# APM32F103x4 register map
File version: 1.0
CPU: CM3 r2p1, little endian, no MPU, no FPU, 4 interrupt priority bits
Registers are 32-bit, read-write, reset 0x0 unless marked. A register's access mark holds for its fields unless they carry their own. Offsets are from the block's base; [hi:lo] are bit positions; {n}, {i} and the like mark numbered series; 'fields as' and 'values as' point back to an identical list.

## DMA1 — DMA1 controller
Base 0x40020000
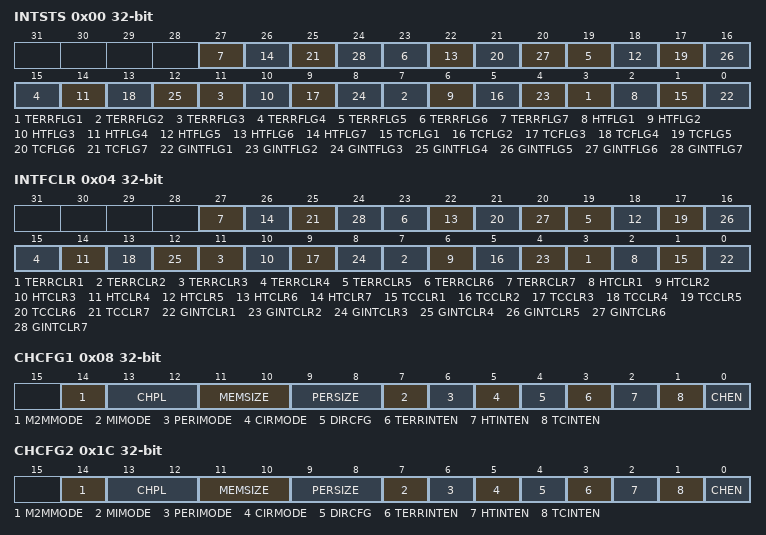
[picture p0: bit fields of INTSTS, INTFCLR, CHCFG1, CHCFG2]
0x00 INTSTS ro — DMA Interrupt status register (DMA_INTSTS)
  [4n-1] TERRFLG{n} (n=1..7) — Channel {n} Transfer Error flag
  [4n-2] HTFLG{n} (n=1..7) — Channel {n} Half Transfer Complete flag
  [4n-3] TCFLG{n} (n=1..7) — Channel {n} Transfer Complete flag
  [4n-4] GINTFLG{n} (n=1..7) — Channel {n} Global interrupt flag
0x04 INTFCLR wo — DMA Interrupt reset register (DMA_INTFCLR)
  [4n-1] TERRCLR{n} (n=1..7) — Channel {n} Transfer Error reset
  [4n-2] HTCLR{n} (n=1..7) — Channel {n} Half Transfer reset
  [4n-3] TCCLR{n} (n=1..7) — Channel {n} Transfer Complete reset
  [4n-4] GINTCLR{n} (n=1..7) — Channel {n} Global interrupt reset
0x08 CHCFG1 — DMA channel 1 configuration register
  [14] M2MMODE — Memory to memory mode
  [13:12] CHPL — Channel Priority level
  [11:10] MEMSIZE — Memory size
  [9:8] PERSIZE — Peripheral size
  [7] MIMODE — Memory increment mode
  [6] PERIMODE — Peripheral increment mode
  [5] CIRMODE — Circular mode
  [4] DIRCFG — Data transfer direction
  [3] TERRINTEN — Transfer error interrupt enable
  [2] HTINTEN — Half Transfer interrupt enable
  [1] TCINTEN — Transfer complete interrupt enable
  [0] CHEN — Channel enable
0x0C CHNDATA1 — DMA channel 1 number of data register
  [15:0] NDATA — Number of data to transfer
0x10 CHPADDR1 — DMA channel 1 peripheral address register
  [31:0] PERADDR — Peripheral address
{0x0+0x14*i} CHMADDR{i} (i=1..7) — DMA channel {i} memory address register
  [31:0] MEMADDR — Memory address
0x1C CHCFG2 — DMA channel 2 configuration register
  fields as CHCFG1
0x20 CHNDATA2 — DMA channel 2 number of data register
  [15:0] NDATA — Number of data to transfer
0x24 CHPADDR2 — DMA channel 2 peripheral address register
  [31:0] PERADDR — Peripheral address
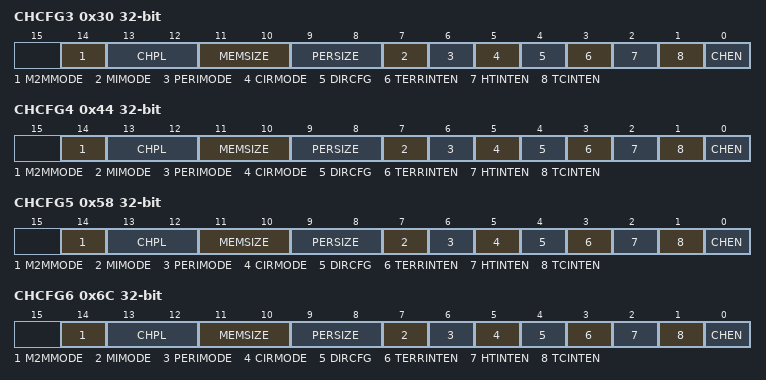
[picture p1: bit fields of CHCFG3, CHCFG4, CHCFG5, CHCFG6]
0x30 CHCFG3 — DMA channel 3 configuration register
  fields as CHCFG1
0x34 CHNDATA3 — DMA channel 3 number of data register
  [15:0] NDATA — Number of data to transfer
0x38 CHPADDR3 — DMA channel 3 peripheral address register
  [31:0] PERADDR — Peripheral address
0x44 CHCFG4 — DMA channel 4 configuration register
  fields as CHCFG1
0x48 CHNDATA4 — DMA channel 4 number of data register
  [15:0] NDATA — Number of data to transfer
0x4C CHPADDR4 — DMA channel 4 peripheral address register
  [31:0] PERADDR — Peripheral address
0x58 CHCFG5 — DMA channel 5 configuration register
  fields as CHCFG1
0x5C CHNDATA5 — DMA channel 5 number of data register
  [15:0] NDATA — Number of data to transfer
0x60 CHPADDR5 — DMA channel 5 peripheral address register
  [31:0] PERADDR — Peripheral address
0x6C CHCFG6 — DMA channel 6 configuration register
  fields as CHCFG1
0x70 CHNDATA6 — DMA channel 6 number of data register
  [15:0] NDATA — Number of data to transfer
0x74 CHPADDR6 — DMA channel 6 peripheral address register
  [31:0] PERADDR — Peripheral address
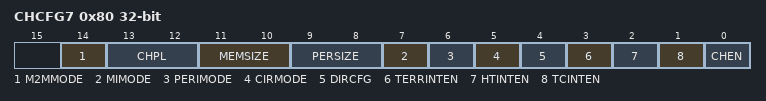
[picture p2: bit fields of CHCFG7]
0x80 CHCFG7 — DMA channel 7 configuration register
  fields as CHCFG1
0x84 CHNDATA7 — DMA channel 7 number of data register
  [15:0] NADDR — Number of data to transfer
0x88 CHPADDR7 — DMA channel 7 peripheral address register
  [31:0] PERADDR — Peripheral address

## USART1 — Universal synchronous asynchronous receiver transmitter
Base 0x40013800
Same registers: USART2 0x40004400
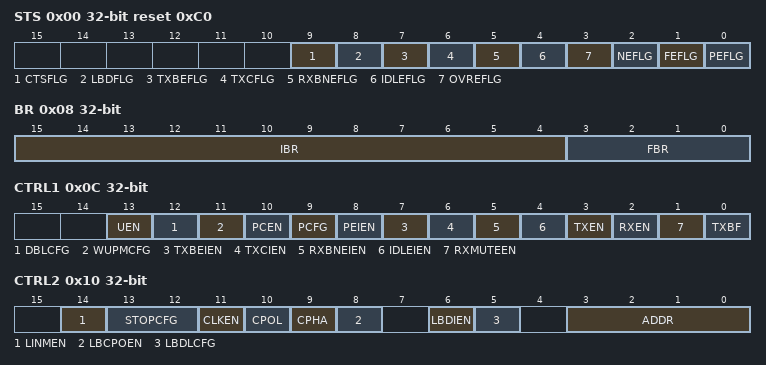
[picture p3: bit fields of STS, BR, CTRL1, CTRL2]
0x00 STS access per field reset 0xC0 — Status register
  [9] CTSFLG rw — CTS flag
  [8] LBDFLG rw — LIN break detection flag
  [7] TXBEFLG ro — Transmit data register empty
  [6] TXCFLG rw — Transmission complete
  [5] RXBNEFLG rw — Read data register not empty
  [4] IDLEFLG ro — IDLE line detected
  [3] OVREFLG ro — Overrun error
  [2] NEFLG ro — Noise error flag
  [1] FEFLG ro — Framing error
  [0] PEFLG ro — Parity error
0x04 DATA — TX Buffer Data Register
  [8:0] DATA — Data value
0x08 BR — Baud rate register
  [15:4] IBR — Integer of USARTDIV
  [3:0] FBR — Fraction of USARTDIV
0x0C CTRL1 — Control register 1
  [13] UEN — USART enable
  [12] DBLCFG — Word length
  [11] WUPMCFG — Wakeup method
  [10] PCEN — Parity control enable
  [9] PCFG — Parity selection
  [8] PEIEN — PE interrupt enable
  [7] TXBEIEN — TXBE interrupt enable
  [6] TXCIEN — Transmission complete interrupt enable
  [5] RXBNEIEN — RXBNE interrupt enable
  [4] IDLEIEN — IDLE interrupt enable
  [3] TXEN — Transmitter enable
  [2] RXEN — Receiver enable
  [1] RXMUTEEN — Receiver wakeup
  [0] TXBF — Send break
0x10 CTRL2 — Control register 2
  [14] LINMEN — LIN mode enable
  [13:12] STOPCFG — STOP bits
  [11] CLKEN — Clock enable
  [10] CPOL — Clock polarity
  [9] CPHA — Clock phase
  [8] LBCPOEN — Last bit clock pulse
  [6] LBDIEN — LIN break detection interrupt enable
  [5] LBDLCFG — lin break detection length
  [3:0] ADDR — Address of the USART node
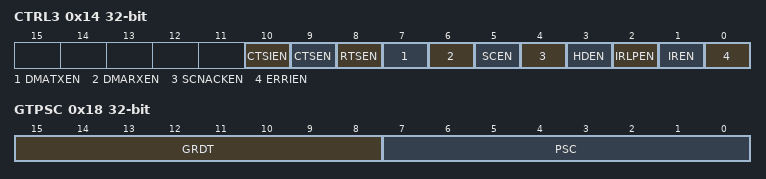
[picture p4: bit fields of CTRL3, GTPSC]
0x14 CTRL3 — Control register 3
  [10] CTSIEN — CTS interrupt enable
  [9] CTSEN — CTS enable
  [8] RTSEN — RTS enable
  [7] DMATXEN — DMA enable transmitter
  [6] DMARXEN — DMA enable receiver
  [5] SCEN — Smartcard mode enable
  [4] SCNACKEN — Smartcard NACK enable
  [3] HDEN — Half-duplex selection
  [2] IRLPEN — IrDA low-power
  [1] IREN — IrDA mode enable
  [0] ERRIEN — Error interrupt enable
0x18 GTPSC — Guard time and divider number register
  [15:8] GRDT — Guard time value
  [7:0] PSC — Prescaler value
